# MSP430G2X12 register map
Vendor: msp430gen; File version: v0.4.0-16-g4f822b9
Registers are 8-bit, read-write, reset 0x0 unless marked. A register's access mark holds for its fields unless they carry their own. Offsets are from the block's base; lines under a group give offsets from that group; [hi:lo] are bit positions; {n}, {i} and the like mark numbered series; 'fields as' and 'values as' point back to an identical list; <NAME> marks a mode.

## Memory map
0x00000000 SPECIAL_FUNCTION
0x00000020 PORT_1_2
0x00000052 SYSTEM_CLOCK
0x00000058 COMPARATOR_A
0x00000078 USI
0x00000120 WATCHDOG_TIMER
0x00000128 FLASH
0x0000012E TIMER0_A3 — Timer A3
0x000010C0 TLV_CALIBRATION_DATA
0x000010F8 CALIBRATION_DATA
0x0000FFE0 _INTERRUPTS

## Interrupts
2 PORT1 (_INTERRUPTS) — 0xFFE4 Port 1
3 PORT2 (_INTERRUPTS) — 0xFFE6 Port 2
4 USI (_INTERRUPTS) — 0xFFE8 USI
8 TIMER0_A1 (_INTERRUPTS) — 0xFFF0 Timer0_A CC1, TA
9 TIMER0_A0 (_INTERRUPTS) — 0xFFF2 Timer0_A CC0
10 WDT (_INTERRUPTS) — 0xFFF4 Watchdog Timer
11 COMPARATORA (_INTERRUPTS) — 0xFFF6 Comparator A
14 NMI (_INTERRUPTS) — 0xFFFC Non-maskable

## SPECIAL_FUNCTION
Base 0x00000000
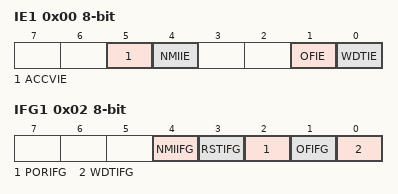
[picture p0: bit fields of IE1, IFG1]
0x00 IE1 — Interrupt Enable 1
  [5] ACCVIE — Flash Access Violation Interrupt Enable
  [4] NMIIE — NMI Interrupt Enable
  [1] OFIE — Osc. Fault Interrupt Enable
  [0] WDTIE — Watchdog Interrupt Enable
0x02 IFG1 — Interrupt Flag 1
  [4] NMIIFG — NMI Interrupt Flag
  [3] RSTIFG — Reset Interrupt Flag
  [2] PORIFG — Power On Interrupt Flag
  [1] OFIFG — Osc. Fault Interrupt Flag
  [0] WDTIFG — Watchdog Interrupt Flag

## PORT_1_2
Base 0x00000020
0x00 P1IN — Port 1 Input
  [n] P{n} (n=0..7)
  [7:0] P1IN — Port 1 Input register
0x01 P1OUT — Port 1 Output
  [n] P{n} (n=0..7)
  [7:0] P1OUT — Port 1 Output register
0x02 P1DIR — Port 1 Direction
  [n] P{n} (n=0..7)
  [7:0] P1DIR — Port 1 Direction register
0x03 P1IFG — Port 1 Interrupt Flag
  [n] P{n} (n=0..7)
  [7:0] P1IFG — Port 1 Interrupt Flag register
0x04 P1IES — Port 1 Interrupt Edge Select
  [n] P{n} (n=0..7)
  [7:0] P1IES — Port 1 Interrupt Edge Select register
0x05 P1IE — Port 1 Interrupt Enable
  [n] P{n} (n=0..7)
  [7:0] P1IE — Port 1 Interrupt Enable register
0x06 P1SEL — Port 1 Selection
  [n] P{n} (n=0..7)
  [7:0] P1SEL — Port 1 Selection register
0x07 P1REN — Port 1 Resistor Enable
  [n] P{n} (n=0..7)
  [7:0] P1REN — Port 1 Resistor Enable register
0x08 P2IN — Port 2 Input
  [n] P{n} (n=0..7)
  [7:0] P2IN — Port 2 Input register
0x09 P2OUT — Port 2 Output
  [n] P{n} (n=0..7)
  [7:0] P2OUT — Port 2 Output register
0x0A P2DIR — Port 2 Direction
  [n] P{n} (n=0..7)
  [7:0] P2DIR — Port 2 Direction register
0x0B P2IFG — Port 2 Interrupt Flag
  [n] P{n} (n=0..7)
  [7:0] P2IFG — Port 2 Interrupt Flag register
0x0C P2IES — Port 2 Interrupt Edge Select
  [n] P{n} (n=0..7)
  [7:0] P2IES — Port 2 Interrupt Edge Select register
0x0D P2IE — Port 2 Interrupt Enable
  [n] P{n} (n=0..7)
  [7:0] P2IE — Port 2 Interrupt Enable register
0x0E P2SEL — Port 2 Selection
  [n] P{n} (n=0..7)
  [7:0] P2SEL — Port 2 Selection register
0x0F P2REN — Port 2 Resistor Enable
  [n] P{n} (n=0..7)
  [7:0] P2REN — Port 2 Resistor Enable register
0x21 P1SEL2 — Port 1 Selection 2
  [n] P{n} (n=0..7)
  [7:0] P1SEL2 — Port 1 Selection register 2
0x22 P2SEL2 — Port 2 Selection 2
  [n] P{n} (n=0..7)
  [7:0] P2SEL2 — Port 2 Selection register 2

## SYSTEM_CLOCK
Base 0x00000052
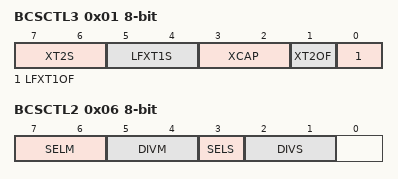
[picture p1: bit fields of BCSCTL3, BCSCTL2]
0x01 BCSCTL3 — Basic Clock System Control 3
  [7:6] XT2S — Mode 0 for XT2
    0=Mode 0 for XT2 : 0.4 - 1 MHz; 1=Mode 1 for XT2 : 1 - 4 MHz; 2=Mode 2 for XT2 : 2 - 16 MHz; 3=Mode 3 for XT2 : Digital input signal
  [5:4] LFXT1S — Mode 0 for LFXT1 (XTS = 0)
    0=Mode 0 for LFXT1 : Normal operation; 1=Mode 1 for LFXT1 : Reserved; 2=Mode 2 for LFXT1 : VLO; 3=Mode 3 for LFXT1 : Digital input signal
  [3:2] XCAP — XIN/XOUT Cap 0
    0=XIN/XOUT Cap : 0 pF; 1=XIN/XOUT Cap : 6 pF; 2=XIN/XOUT Cap : 10 pF; 3=XIN/XOUT Cap : 12.5 pF
  [1] XT2OF — High frequency oscillator 2 fault flag
  [0] LFXT1OF — Low/high Frequency Oscillator Fault Flag
0x04 DCOCTL — DCO Clock Frequency Control
  [7:5] DCO — DCO Select Bit 0
  [7:0] DCOCTL — DCO Clock Frequency Control register
  [4:0] MOD — Modulation Bit 0
0x05 BCSCTL1 — Basic Clock System Control 1
  [7] XT2OFF — Enable XT2CLK
  [6] XTS — LFXTCLK 0:Low Freq. / 1: High Freq.
  [5:4] DIVA — ACLK Divider 0
    0=ACLK Divider 0: /1; 1=ACLK Divider 1: /2; 2=ACLK Divider 2: /4; 3=ACLK Divider 3: /8
  [7:0] BCSCTL1 — Basic Clock System Control 1 register
  [3:0] RSEL — Range Select Bit 0
0x06 BCSCTL2 — Basic Clock System Control 2
  [7:6] SELM — MCLK Source Select 0
    0=MCLK Source Select 0: DCOCLK; 1=MCLK Source Select 1: DCOCLK; 2=MCLK Source Select 2: XT2CLK/LFXTCLK; 3=MCLK Source Select 3: LFXTCLK
  [5:4] DIVM — MCLK Divider 0
    0=MCLK Divider 0: /1; 1=MCLK Divider 1: /2; 2=MCLK Divider 2: /4; 3=MCLK Divider 3: /8
  [3] SELS — SMCLK Source Select 0:DCOCLK / 1:XT2CLK/LFXTCLK
  [2:1] DIVS — SMCLK Divider 0
    0=SMCLK Divider 0: /1; 1=SMCLK Divider 1: /2; 2=SMCLK Divider 2: /4; 3=SMCLK Divider 3: /8
